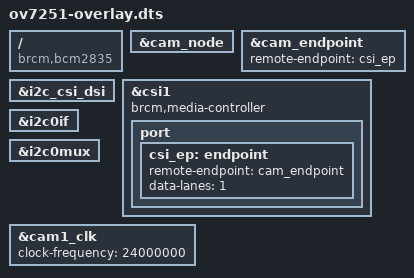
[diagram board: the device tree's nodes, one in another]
// SPDX-License-Identifier: GPL-2.0-only
// Definitions for OV7251 camera module on VC I2C bus
/dts-v1/;
/plugin/;

#include <dt-bindings/gpio/gpio.h>

/{
	compatible = "brcm,bcm2835";

	i2c_frag: fragment@0 {
		target = <&i2c_csi_dsi>;
		__overlay__ {
			#address-cells = <1>;
			#size-cells = <0>;
			status = "okay";

			#include "ov7251.dtsi"
		};
	};

	csi_frag: fragment@1 {
		target = <&csi1>;
		csi: __overlay__ {
			status = "okay";
			brcm,media-controller;

			port {
				csi_ep: endpoint {
					remote-endpoint = <&cam_endpoint>;
					data-lanes = <1>;
				};
			};
		};
	};

	fragment@2 {
		target = <&i2c0if>;
		__overlay__ {
			status = "okay";
		};
	};

	fragment@3 {
		target = <&i2c0mux>;
		__overlay__ {
			status = "okay";
		};
	};

	clk_frag: fragment@4 {
		target = <&cam1_clk>;
		__overlay__ {
			status = "okay";
			clock-frequency = <24000000>;
		};
	};

	__overrides__ {
		rotation = <&cam_node>,"rotation:0";
		orientation = <&cam_node>,"orientation:0";
		media-controller = <&csi>,"brcm,media-controller?";
		cam0 = <&i2c_frag>, "target:0=",<&i2c_csi_dsi0>,
		       <&csi_frag>, "target:0=",<&csi0>,
		       <&clk_frag>, "target:0=",<&cam0_clk>,
		       <&cam_node>, "clocks:0=",<&cam0_clk>,
		       <&cam_node>, "vdda-supply:0=",<&cam0_reg>;
	};
};

&cam_node {
	status = "okay";
};

&cam_endpoint {
	remote-endpoint = <&csi_ep>;
};
